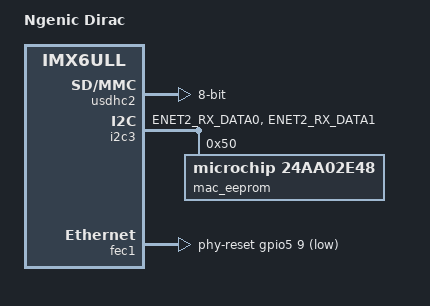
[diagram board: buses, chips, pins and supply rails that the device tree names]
// SPDX-License-Identifier: GPL-2.0
/*
 * Copyright (C) 2020 Linumiz
 * Author: Parthiban Nallathambi <parthiban@linumiz.com>
 */

/dts-v1/;
#include "imx6ull.dtsi"
#include "imx6ull-myir-mys-6ulx.dtsi"

/*
 * As a general strategy, we inherit the upstream board
 * and then override what we need. Less work that way.
 */

/ {
	model = "Ngenic Dirac";
	compatible = "ngenic,dirac", "fsl,imx6ull";

	chosen {
		mac,eeprom = &mac_eeprom;
	};
};

&usdhc1 {
	status = "disabled";
};

&usdhc2 {
	status = "okay";
	// dirac has V2 SoM which has working 8-bit
	bus-width = <8>;
};

&iomuxc {
	pinctrl_i2c3: i2c3grp {
		fsl,pins = <
			MX6UL_PAD_ENET2_RX_DATA0__I2C3_SCL 0x4001b8b0
			MX6UL_PAD_ENET2_RX_DATA1__I2C3_SDA 0x4001b8b0
		>;
	};
};

&iomuxc_snvs {
	pinctrl_ethphy1_reset: hoggrp-2 {
		fsl,pins = <
			MX6ULL_PAD_SNVS_TAMPER9__GPIO5_IO09     0x1b0b0 /* enet1 reset - module internal! */
		>;
	};
};


&i2c3 {
	pinctrl-names = "default";
	pinctrl-0 = <&pinctrl_i2c3>;
	clock_frequency = <100000>;
	status = "okay";

	mac_eeprom: eeprom@50 {
		compatible = "microchip,24aa02e48";
		reg = <0x50>;
		pagesize = <8>;
	};
};

&fec1 {
	phy-reset-gpios = <&gpio5 9 GPIO_ACTIVE_LOW>;
	phy-reset-duration = <26>;
};
